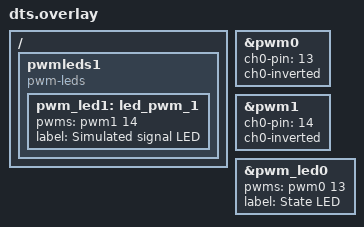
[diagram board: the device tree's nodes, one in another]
/ {
	pwmleds1 {
		compatible = "pwm-leds";
		status = "okay";

		pwm_led1: led_pwm_1 {
			status = "okay";
			pwms = <&pwm1 14>;
			label = "Simulated signal LED";
		};
	};
};

&pwm0 {
	status = "okay";
	ch0-pin = <13>;
	ch0-inverted;
};

&pwm1 {
	status = "okay";
	ch0-pin = <14>;
	ch0-inverted;
};

&pwm_led0 {
	status = "okay";
	pwms = <&pwm0 13>;
	label = "State LED";
};
